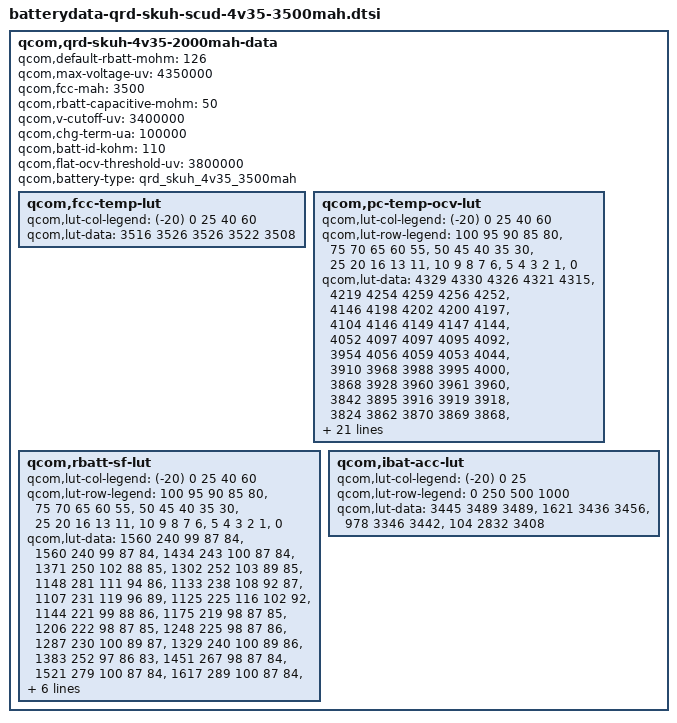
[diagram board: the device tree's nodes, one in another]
/* Copyright (c) 2014, The Linux Foundation. All rights reserved.
 *
 * This program is free software; you can redistribute it and/or modify
 * it under the terms of the GNU General Public License version 2 and
 * only version 2 as published by the Free Software Foundation.
 *
 * This program is distributed in the hope that it will be useful,
 * but WITHOUT ANY WARRANTY; without even the implied warranty of
 * MERCHANTABILITY or FITNESS FOR A PARTICULAR PURPOSE.  See the
 * GNU General Public License for more details.
 */

qcom,qrd-skuh-4v35-2000mah-data {
	qcom,default-rbatt-mohm = <126>;
	qcom,max-voltage-uv = <4350000>;
	qcom,fcc-mah = <3500>;
	qcom,rbatt-capacitive-mohm = <50>;
	qcom,v-cutoff-uv = <3400000>;
	qcom,chg-term-ua = <100000>;
	qcom,batt-id-kohm = <110>;
	qcom,flat-ocv-threshold-uv = <3800000>;
	qcom,battery-type = "qrd_skuh_4v35_3500mah";

	qcom,fcc-temp-lut {
		qcom,lut-col-legend = <(-20) 0 25 40 60>;
		qcom,lut-data = <3516 3526 3526 3522 3508>;
	};

	qcom,pc-temp-ocv-lut {
		qcom,lut-col-legend = <(-20) 0 25 40 60>;
		qcom,lut-row-legend = <100 95 90 85 80>,
				<75 70 65 60 55>,
				<50 45 40 35 30>,
				<25 20 16 13 11>,
				<10 9 8 7 6>,
				<5 4 3 2 1>,
				<0>;
		qcom,lut-data = <4329 4330 4326 4321 4315>,
				<4219 4254 4259 4256 4252>,
				<4146 4198 4202 4200 4197>,
				<4104 4146 4149 4147 4144>,
				<4052 4097 4097 4095 4092>,
				<3954 4056 4059 4053 4044>,
				<3910 3968 3988 3995 4000>,
				<3868 3928 3960 3961 3960>,
				<3842 3895 3916 3919 3918>,
				<3824 3862 3870 3869 3868>,
				<3808 3834 3840 3840 3840>,
				<3794 3812 3818 3818 3818>,
				<3780 3794 3801 3800 3798>,
				<3766 3782 3786 3785 3784>,
				<3752 3770 3772 3768 3764>,
				<3736 3758 3756 3747 3734>,
				<3718 3742 3738 3728 3716>,
				<3702 3722 3718 3710 3696>,
				<3686 3706 3700 3691 3678>,
				<3672 3698 3690 3683 3672>,
				<3664 3695 3689 3682 3670>,
				<3654 3692 3688 3680 3669>,
				<3642 3688 3686 3678 3666>,
				<3626 3684 3682 3675 3662>,
				<3607 3676 3674 3666 3652>,
				<3582 3654 3651 3638 3621>,
				<3548 3614 3608 3594 3578>,
				<3503 3560 3552 3536 3520>,
				<3437 3486 3478 3460 3444>,
				<3328 3375 3366 3343 3330>,
				<3100 3128 3128 3100 3106>;
	};

	qcom,rbatt-sf-lut {
		qcom,lut-col-legend = <(-20) 0 25 40 60>;
		qcom,lut-row-legend = <100 95 90 85 80>,
				<75 70 65 60 55>,
				<50 45 40 35 30>,
				<25 20 16 13 11>,
				<10 9 8 7 6>,
				<5 4 3 2 1>,
				<0>;
		qcom,lut-data = <1560 240 99 87 84>,
				<1560 240 99 87 84>,
				<1434 243 100 87 84>,
				<1371 250 102 88 85>,
				<1302 252 103 89 85>,
				<1148 281 111 94 86>,
				<1133 238 108 92 87>,
				<1107 231 119 96 89>,
				<1125 225 116 102 92>,
				<1144 221 99 88 86>,
				<1175 219 98 87 85>,
				<1206 222 98 87 85>,
				<1248 225 98 87 86>,
				<1287 230 100 89 87>,
				<1329 240 100 89 86>,
				<1383 252 97 86 83>,
				<1451 267 98 87 84>,
				<1521 279 100 87 84>,
				<1617 289 100 87 84>,
				<1630 291 99 86 84>,
				<1567 291 100 87 84>,
				<1660 302 101 87 86>,
				<1791 315 103 89 88>,
				<1960 333 105 93 90>,
				<2169 349 108 94 90>,
				<2430 362 105 89 86>,
				<2786 375 104 90 87>,
				<3278 410 106 92 87>,
				<3992 464 112 95 90>,
				<5808 539 125 107 102>,
				<11616 1078 251 214 203>;
	};

	qcom,ibat-acc-lut {
		qcom,lut-col-legend = <(-20) 0 25>;
		qcom,lut-row-legend = <0 250 500 1000>;
		qcom,lut-data = <3445 3489 3489>,
				<1621 3436 3456>,
				<978 3346 3442>,
				<104 2832 3408>;
	};
};
